# RS1xxxx register map
Vendor: Silicon Lab Inc.; Series: ARMCM4; File version: 1.2
CPU: CM4 r1p0, little endian, MPU, FPU, 6 interrupt priority bits
Registers are 32-bit, read-write, reset 0x0 unless marked. A register's access mark holds for its fields unless they carry their own. Offsets are from the block's base; [hi:lo] are bit positions; lines under a group give offsets from that group; {n}, {i} and the like mark numbered series; 'fields as' and 'values as' point back to an identical list.

## SDIO_Slave — The Secure Digital I/O (SDIO) Slave module implements the functionality of the SDIO card based on the SDIO specifications version 2.0.
Base 0x20200000
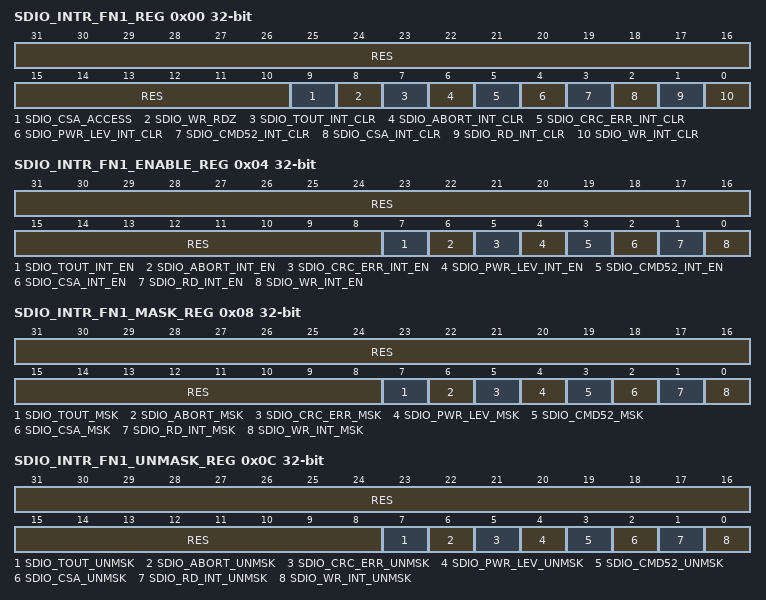
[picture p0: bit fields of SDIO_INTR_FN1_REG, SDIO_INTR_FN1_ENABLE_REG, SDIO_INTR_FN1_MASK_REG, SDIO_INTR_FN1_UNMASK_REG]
0x00 SDIO_INTR_FN1_REG — SDIO Function1 Interrupt Enable Register
  [31:10] RES — reserved1
  [9] SDIO_CSA_ACCESS — csa_window_access When set, indicates that current request is for CSA window register. This is only status signal
  [8] SDIO_WR_RDZ
  [7] SDIO_TOUT_INT_CLR — This bit is used to enable ?read FIFO wait time over? interrupt
  [6] SDIO_ABORT_INT_CLR — This bit is used to enable abort interrupt
  [5] SDIO_CRC_ERR_INT_CLR — This bit is used to enable CRC error interrupt
  [4] SDIO_PWR_LEV_INT_CLR — This bit is used to enable power level change interrupt
  [3] SDIO_CMD52_INT_CLR — This bit is used to enable CMD52 interrupt
  [2] SDIO_CSA_INT_CLR — This bit is used to enable CMD53 CSA interrupt
  [1] SDIO_RD_INT_CLR — This bit is used to enable CMD53 read interrupt
  [0] SDIO_WR_INT_CLR — This bit is used to enable CMD53 write interrupt. =1 Interrupt is enabled =0 - Interrupt is disabled
0x04 SDIO_INTR_FN1_ENABLE_REG — SDIO Function1 Interrupt Enable Register
  [31:8] RES — reserved5
  [7] SDIO_TOUT_INT_EN — This bit is used to enable ?read FIFO wait time over? interrupt
  [6] SDIO_ABORT_INT_EN — This bit is used to enable abort interrupt
  [5] SDIO_CRC_ERR_INT_EN — This bit is used to enable CRC error interrupt
  [4] SDIO_PWR_LEV_INT_EN — This bit is used to enable power level change interrupt
  [3] SDIO_CMD52_INT_EN — This bit is used to enable CMD52 interrupt
  [2] SDIO_CSA_INT_EN — This bit is used to enable CMD53 CSA interrupt
  [1] SDIO_RD_INT_EN — This bit is used to enable CMD53 read interrupt
  [0] SDIO_WR_INT_EN — This bit is used to enable CMD53 write interrupt.
0x08 SDIO_INTR_FN1_MASK_REG — SDIO Function1 Interrupt Mask Register
  [31:8] RES — reserved5
  [7] SDIO_TOUT_MSK — This bit is used to mask read FIFO wait time over interrupt
  [6] SDIO_ABORT_MSK — This bit is used to mask abort interrupt Setting this bit will mask the interrupt Clearing this bit has no effect
  [5] SDIO_CRC_ERR_MSK — This bit is used to mask CRC error interrupt
  [4] SDIO_PWR_LEV_MSK — This bit is used to mask power level change interrupt
  [3] SDIO_CMD52_MSK — This bit is used to mask CMD52 interrupt
  [2] SDIO_CSA_MSK — This bit is used to mask CMD53 CSA interrupt.Setting this bit will mask the interrupt Clearing this bit has no effect
  [1] SDIO_RD_INT_MSK — This bit is used to mask CMD53 read interrupt
  [0] SDIO_WR_INT_MSK — This bit is used to mask CMD53 write interrupt
0x0C SDIO_INTR_FN1_UNMASK_REG — SDIO Function1 Interrupt UnMask Register
  [31:8] RES — reserved5
  [7] SDIO_TOUT_UNMSK — This bit is used to unmask read FIFO wait time over interrupt
  [6] SDIO_ABORT_UNMSK — This bit is used to unmask abort interrupt Setting this bit will mask the interrupt Clearing this bit has no effect
  [5] SDIO_CRC_ERR_UNMSK — This bit is used to unmask CRC error interrupt
  [4] SDIO_PWR_LEV_UNMSK — This bit is used to unmask power level change interrupt
  [3] SDIO_CMD52_UNMSK — This bit is used to unmask CMD52 interrupt
  [2] SDIO_CSA_UNMSK — This bit is used to unmask CMD53 CSA interrupt.Setting this bit will mask the interrupt Clearing this bit has no effect
  [1] SDIO_RD_INT_UNMSK — This bit is used to unmask CMD53 read interrupt
  [0] SDIO_WR_INT_UNMSK — This bit is used to unmask CMD53 write interrupt
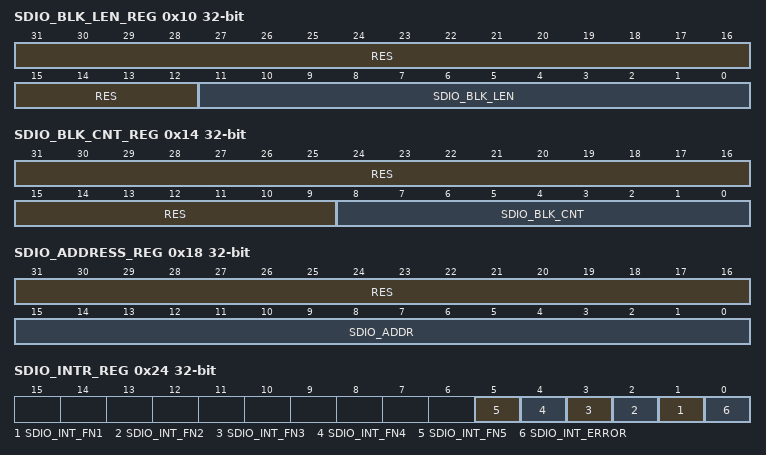
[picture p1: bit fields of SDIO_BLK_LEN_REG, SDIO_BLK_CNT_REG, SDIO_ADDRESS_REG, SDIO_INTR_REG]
0x10 SDIO_BLK_LEN_REG ro — SDIO Block Length Register
  [31:12] RES — reserved5
  [11:0] SDIO_BLK_LEN — Length of each block for the last received CMD53
0x14 SDIO_BLK_CNT_REG ro — SDIO Block Length Register
  [31:9] RES — reserved5
  [8:0] SDIO_BLK_CNT — Block count for the last received CMD53
0x18 SDIO_ADDRESS_REG ro — SDIO Address Register
  [31:16] RES — reserved5
  [15:0] SDIO_ADDR — Lower 16-bits of the 17-bit address field in the last received CMD53
0x1C SDIO_CMD52_RDATA_REGISTER ro — SDIO CMD52 Read data Register
  [7:0] RDATA — Data to be given to host for CMD52 slave mode access read command has to written into this register
0x20 SDIO_CMD52_WDATA_REGISTER ro reset 0xFF — SDIO CMD52 Write data Register
  [7:0] WDATA — Data from host in CMD52 slave mode access write command is available in this register
0x24 SDIO_INTR_REG ro — SDIO Interrupt Status Register
  [n] SDIO_INT_FN{n} (n=1..5) — Interrupt is pending for function{n}
  [0] SDIO_INT_ERROR — Interrupt is pending because of error condition from any of the functions
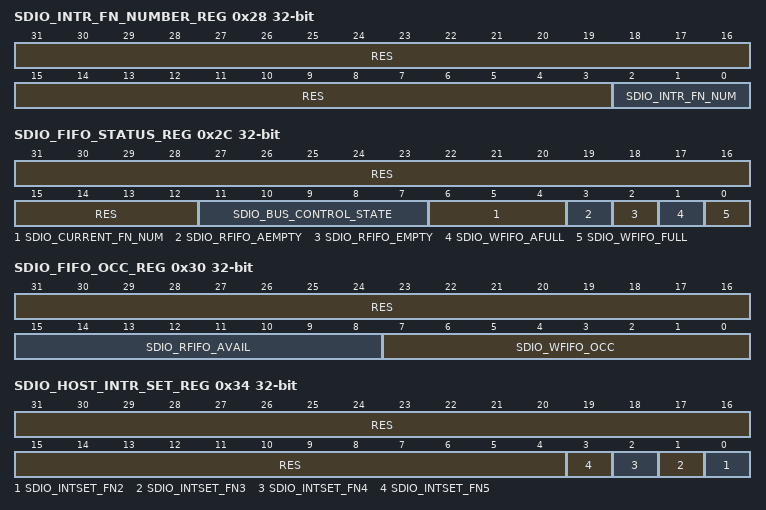
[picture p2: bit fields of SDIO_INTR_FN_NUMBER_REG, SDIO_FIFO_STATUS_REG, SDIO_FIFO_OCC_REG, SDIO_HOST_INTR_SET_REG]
0x28 SDIO_INTR_FN_NUMBER_REG ro — SDIO Interrupt Function Number Register
  [31:3] RES — reserved5
  [2:0] SDIO_INTR_FN_NUM — Indicates the function number to which interrupt is pending.
0x2C SDIO_FIFO_STATUS_REG ro — SDIO FIFO Status Register
  [31:12] RES — reserved5
  [11:7] SDIO_BUS_CONTROL_STATE — Indicates the function number of the last received command
  [6:4] SDIO_CURRENT_FN_NUM — Indicates the function number of the last received command
  [3] SDIO_RFIFO_AEMPTY — When set, indicates that RFIFO is almost empty
  [2] SDIO_RFIFO_EMPTY — When set, indicates that RFIFO is empty RFIFO is used in SDIO writes from host for sending data from host to AHB
  [1] SDIO_WFIFO_AFULL — When set, indicates that WFIFO is almost full
  [0] SDIO_WFIFO_FULL — When set, indicates that WFIFO is full WFIFO is used in SDIO reads from host for sending data from AHB to Host
0x30 SDIO_FIFO_OCC_REG ro — SDIO FIFO Occupancy Register
  [31:16] RES — reserved5
  [15:8] SDIO_RFIFO_AVAIL — Indicates the available space in the read FIFO
  [7:0] SDIO_WFIFO_OCC — Indicates the occupancy level of the write FIFO
0x34 SDIO_HOST_INTR_SET_REG — SDIO Host Interrupt Set Register
  [31:4] RES — reserved5
  [n-2] SDIO_INTSET_FN{n} (n=2..5) — This bit is used to raise an interrupt to host for function{n}. Setting this bit will raise the interrupt Clearing this bit has no effect
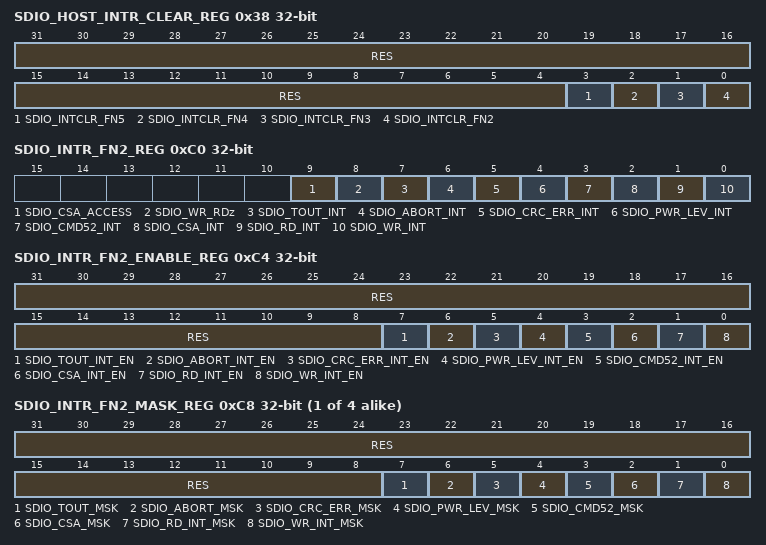
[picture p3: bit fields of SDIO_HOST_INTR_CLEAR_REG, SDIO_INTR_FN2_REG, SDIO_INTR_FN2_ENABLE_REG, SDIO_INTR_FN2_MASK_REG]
0x38 SDIO_HOST_INTR_CLEAR_REG — SDIO Host Interrupt Clear Register
  [31:4] RES — reserved5
  [3] SDIO_INTCLR_FN5 — This bit is used to clear the interrupt to host for function5. Setting this bit will clear the interrupt Clearing this bit has no effect
  [2] SDIO_INTCLR_FN4 — This bit is used to clear the interrupt to host for function4. Setting this bit will clear the interrupt Clearing this bit has no effectt
  [1] SDIO_INTCLR_FN3 — This bit is used to clear the interrupt to host for function3. Setting this bit will clear the interrupt Clearing this bit has no effect
  [0] SDIO_INTCLR_FN2 — This bit is used to clear the interrupt to host for function2. Setting this bit will clear the interrupt Clearing this bit has no effect
{0x40+4i} SDIO_RFIFO_DATA_REGn[{i}] (i=0..15) group — SDIO Read FIFO Data Register (0-15)
  0x00 SDIO_RFIFO_DATA_REG_n_ wo — SDIO Read FIFO Data Register
    [31:0] SDIO_RFIFO — Data to be written into SDIO Read FIFO has to be written in this register.
{0x80+4i} SDIO_WFIFO_DATA_REGn[{i}] (i=0..15) group — SDIO Write FIFO Data Register (0-15)
  0x00 SDIO_WFIFO_DATA_REG_n_ ro — SDIO Write FIFO Data Register
    [31:0] SDIO_WFIFO — SDIO Write FIFO data can be read through this register.
0xC0 SDIO_INTR_FN2_REG — SDIO interrupt Function2
  [9] SDIO_CSA_ACCESS — csa_window_access When set, indicates that current request is for CSA window register. This is only status signal
  [8] SDIO_WR_RDz — wr_rdz, This is not an interrupt signal. This is only status signal
  [7] SDIO_TOUT_INT — This bit is used to enable ?read FIFO wait time over? interrupt
  [6] SDIO_ABORT_INT — This bit is used to enable abort interrupt
  [5] SDIO_CRC_ERR_INT — This bit is used to enable CRC error interrupt
  [4] SDIO_PWR_LEV_INT — This bit is used to enable power level change interrupt
  [3] SDIO_CMD52_INT — This bit is used to enable CMD52 interrupt
  [2] SDIO_CSA_INT — This bit is used to enable CMD53 CSA interrupt
  [1] SDIO_RD_INT — This bit is used to enable CMD53 read interrupt
  [0] SDIO_WR_INT — This bit is used to enable CMD53 write interrupt. =1 Interrupt is enabled =0 - Interrupt is disabled
0xC4 SDIO_INTR_FN2_ENABLE_REG — SDIO Function1 Interrupt Enable Register
  fields as SDIO_INTR_FN1_ENABLE_REG
{0xA8+0x10*i} SDIO_INTR_FN{i}_MASK_REG (i=2..5) — SDIO Function{i} Interrupt Mask Register
  fields as SDIO_INTR_FN1_MASK_REG
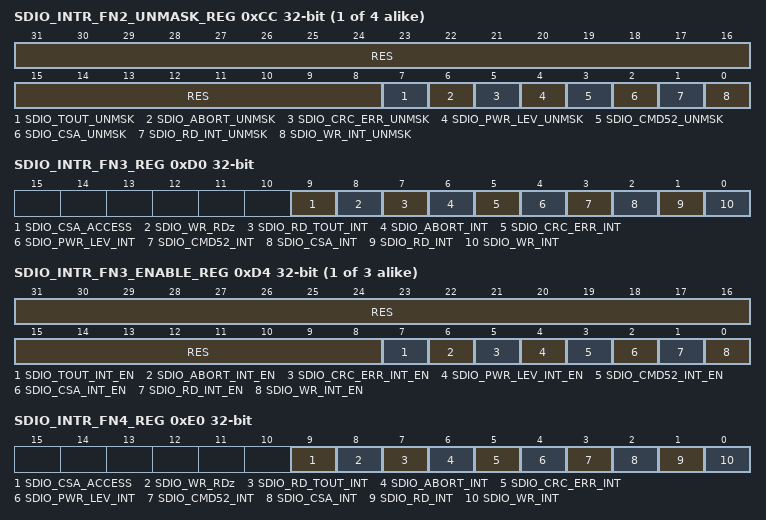
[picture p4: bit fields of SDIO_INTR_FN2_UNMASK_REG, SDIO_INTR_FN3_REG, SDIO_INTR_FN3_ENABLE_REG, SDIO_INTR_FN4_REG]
{0xAC+0x10*i} SDIO_INTR_FN{i}_UNMASK_REG (i=2..5) — SDIO Function{i} Interrupt Mask Register
  fields as SDIO_INTR_FN1_UNMASK_REG
0xD0 SDIO_INTR_FN3_REG — SDIO interrupt Function3
  [9] SDIO_CSA_ACCESS — csa_window_access When set, indicates that current request is for CSA window register. This is only status signal
  [8] SDIO_WR_RDz — wr_rdz, This is not an interrupt signal. This is only status signal
  [7] SDIO_RD_TOUT_INT — This bit is used to enable ?read FIFO wait time over? interrupt
  [6] SDIO_ABORT_INT — This bit is used to enable abort interrupt
  [5] SDIO_CRC_ERR_INT — This bit is used to enable CRC error interrupt
  [4] SDIO_PWR_LEV_INT — This bit is used to enable power level change interrupt
  [3] SDIO_CMD52_INT — This bit is used to enable CMD52 interrupt
  [2] SDIO_CSA_INT — This bit is used to enable CMD53 CSA interrupt
  [1] SDIO_RD_INT — This bit is used to enable CMD53 read interrupt
  [0] SDIO_WR_INT — This bit is used to enable CMD53 write interrupt. =1 Interrupt is enabled =0 - Interrupt is disabled
{0xA4+0x10*i} SDIO_INTR_FN{i}_ENABLE_REG (i=3..5) — SDIO Function{i} Interrupt Enable Register
  fields as SDIO_INTR_FN1_ENABLE_REG
0xE0 SDIO_INTR_FN4_REG — SDIO interrupt Function4
  fields as SDIO_INTR_FN3_REG
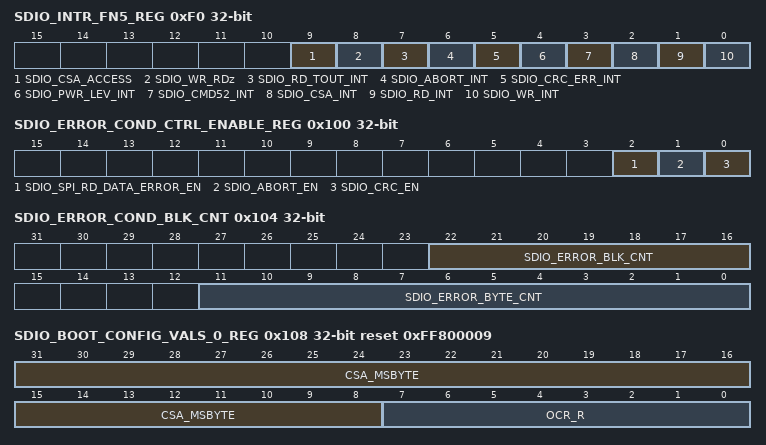
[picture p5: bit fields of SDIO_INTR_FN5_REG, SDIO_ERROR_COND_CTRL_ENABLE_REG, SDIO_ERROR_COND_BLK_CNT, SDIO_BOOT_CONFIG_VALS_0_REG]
0xF0 SDIO_INTR_FN5_REG — SDIO interrupt Function5 Register
  fields as SDIO_INTR_FN3_REG
0x100 SDIO_ERROR_COND_CTRL_ENABLE_REG — SDIO error condition Control enable register
  [2] SDIO_SPI_RD_DATA_ERROR_EN — When set, stops the DMA from doing data accesses till read data error interrupt is cleared in SPI mode
  [1] SDIO_ABORT_EN — When set, stops the DMA from doing data accesses till ABORT interrupt is cleared
  [0] SDIO_CRC_EN — When set, stops the DMA from doing data accesses till CRC error interrupt is cleared
0x104 SDIO_ERROR_COND_BLK_CNT — SDIO error condition block count register
  [22:16] SDIO_ERROR_BLK_CNT — Indicates block count when one of error condition occurred
  [11:0] SDIO_ERROR_BYTE_CNT — Indicates byte count when one of the error condition occurred
0x108 SDIO_BOOT_CONFIG_VALS_0_REG ro reset 0xFF800009 — SDIO Boot Config Values Register 0
  [31:8] CSA_MSBYTE — MS byre of CSA address. Lower 24 bits of CSA will come through SDIO CSA registers. Whenever CSA access is done, 32-bit address will be prepared using these fields.
  [7:0] OCR_R — Operating conditions. The value written by bootloader can be read here.
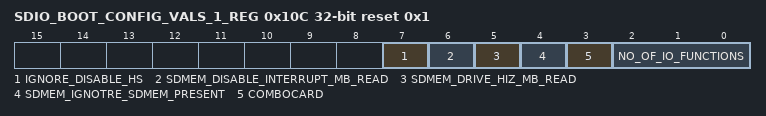
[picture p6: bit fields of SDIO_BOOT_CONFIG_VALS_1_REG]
0x10C SDIO_BOOT_CONFIG_VALS_1_REG ro reset 0x1 — SDIO Boot Config Values Register 1
  [7] IGNORE_DISABLE_HS — if ignore_disable_hs is set, sdmem_disable_high_speed_switching coming from combo mode module is ignored
  [6] SDMEM_DISABLE_INTERRUPT_MB_READ — When set, interrupt will be not be driven during sd memory mb read transfer
  [5] SDMEM_DRIVE_HIZ_MB_READ — When set, High will be driven in the second cycle of interrupt period during sd memory mb read transfer
  [4] SDMEM_IGNOTRE_SDMEM_PRESENT — When set, sdmem_present signal, coming from GPIO, will be ignored.
  [3] COMBOCARD — When set, combo mode will be enabled.
  [2:0] NO_OF_IO_FUNCTIONS — Indicates number functions supported. The value written by bootloader can be read here.
